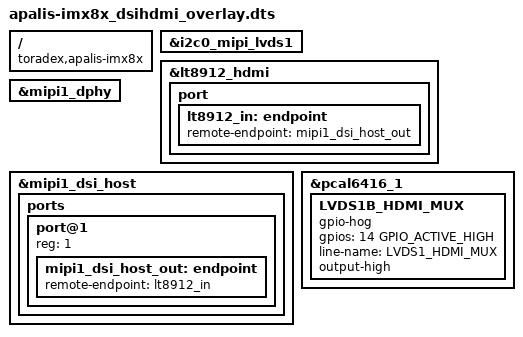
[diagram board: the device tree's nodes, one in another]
// SPDX-License-Identifier: GPL-2.0-or-later OR MIT
/*
 * Copyright 2020-2021 Toradex
 */

// Turn on a an HDMI interface on Apalis-iMX8X

/dts-v1/;
/plugin/;

#include <dt-bindings/gpio/gpio.h>

/ {
	compatible = "toradex,apalis-imx8x";
};

&i2c0_mipi_lvds1 {
	status = "okay";
};

&lt8912_hdmi {
	status = "okay";

	port {
		lt8912_in: endpoint {
			remote-endpoint = <&mipi1_dsi_host_out>;
		};
	};
};

&mipi1_dphy {
	status = "okay";
};

&mipi1_dsi_host {
	status = "okay";

	ports {
		#address-cells = <1>;
		#size-cells = <0>;

		port@1 {
			reg = <1>;

			mipi1_dsi_host_out: endpoint {
				remote-endpoint = <&lt8912_in>;
			};
		};
	};
};

/* On-module GPIO Expander */
&pcal6416_1 {
	/*
	 * This gpio-hog drives a muxing device. With that we can choose
	 * if LVDS1_B pins are active or if DSI signals routed to the
	 * on-module Lontium LT8912 DSI-to-HDMI bridge chip are active.
	 *
	 * output-high; muxes to DSI signals, getting Apalis HDMI1 pins active
	 * output-low; muxes to LVDS1_B signals, getting Apalis LVDS1 pins active
	 */
	 LVDS1B_HDMI_MUX {
		gpio-hog;
		gpios = <14 GPIO_ACTIVE_HIGH>;
		line-name = "LVDS1_HDMI_MUX";
		output-high;
	};
};
